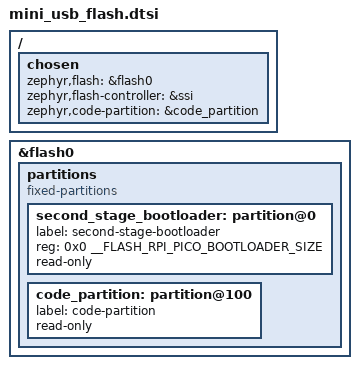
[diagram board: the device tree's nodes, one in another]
/*
 * Copyright (c) 2025 TiaC Systems
 * SPDX-License-Identifier: Apache-2.0
 */

#define __FLASH_RPI_PICO_BOOTLOADER_SIZE	0x100

/ {
	chosen {
		zephyr,flash = &flash0;
		zephyr,flash-controller = &ssi;
		zephyr,code-partition = &code_partition;
	};
};

&flash0 {
	partitions {
		compatible = "fixed-partitions";
		#address-cells = <1>;
		#size-cells = <1>;

		/* Reserved memory for the second stage bootloader */
		second_stage_bootloader: partition@0 {
			label = "second-stage-bootloader";
			reg = <0x0 __FLASH_RPI_PICO_BOOTLOADER_SIZE>;
			read-only;
		};

		/* Rest for code */
		code_partition: partition@100 {
			label = "code-partition";
			read-only;
		};
	};
};
